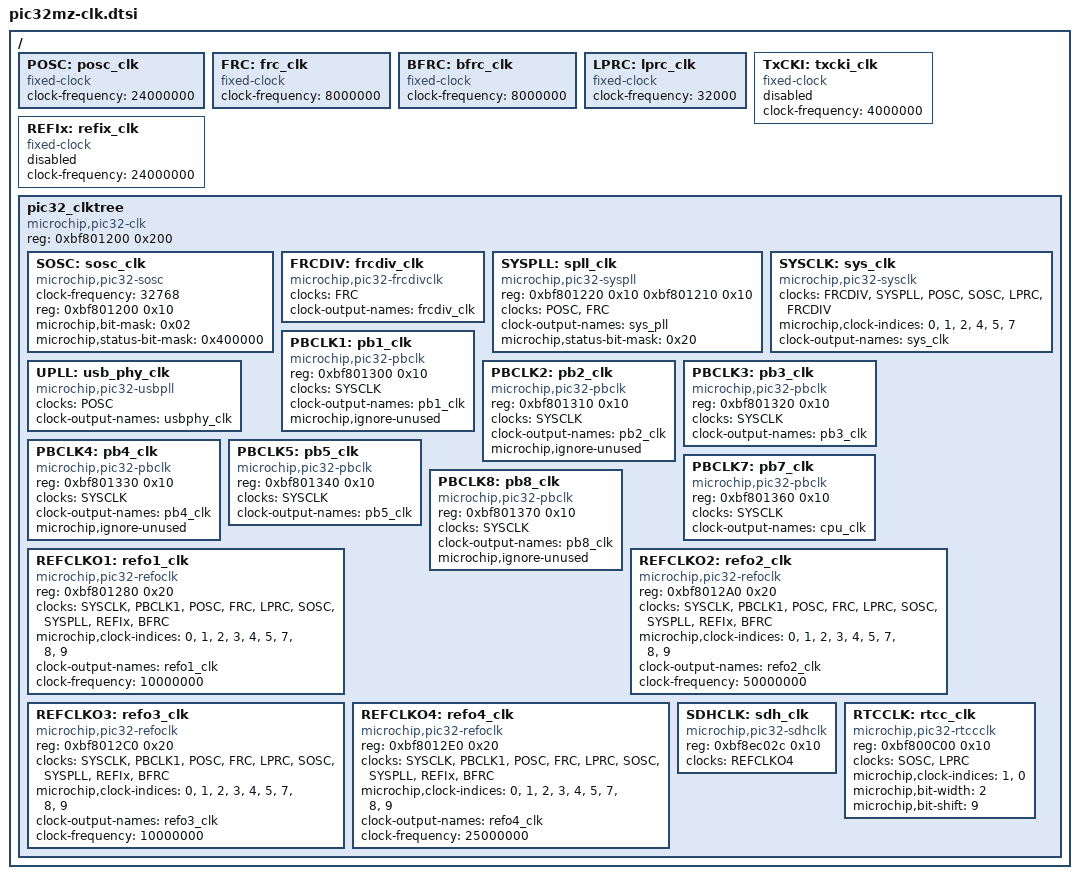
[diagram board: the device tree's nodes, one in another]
/*
 * Device Tree Source for PIC32MZ clock data
 *
 * Copyright (C) 2014 Microchip Technology, Inc.
 *               2014 Purna Chandra Mandal <purna.mandal@microchip.com>
 *
 * Licensed under GPLv2 or later.
 */

/* all fixed rate clocks */

/ {
	POSC:posc_clk { /* On-chip primary oscillator */
		#clock-cells = <0>;
		compatible = "fixed-clock";
		clock-frequency = <24000000>;
	};

	FRC:frc_clk { /* internal FRC oscillator */
		#clock-cells = <0>;
		compatible = "fixed-clock";
		clock-frequency = <8000000>;
	};

	BFRC:bfrc_clk { /* internal backup FRC oscillator */
		#clock-cells = <0>;
		compatible = "fixed-clock";
		clock-frequency = <8000000>;
	};

	LPRC:lprc_clk { /* internal low-power FRC oscillator */
		#clock-cells = <0>;
		compatible = "fixed-clock";
		clock-frequency = <32000>;
	};

	TxCKI:txcki_clk { /* external clock input on TxCLKI pin */
		#clock-cells = <0>;
		compatible = "fixed-clock";
		clock-frequency = <4000000>;
		status = "disabled";
	};

	/* external clock input on REFCLKIx pin */
	REFIx:refix_clk {
		#clock-cells = <0>;
		compatible = "fixed-clock";
		clock-frequency = <24000000>;
		status = "disabled";
	};

	/* PIC32 specifc clks */
	pic32_clktree {
		#address-cells = <1>;
		#size-cells = <1>;
		reg = <0xbf801200 0x200>;
		compatible = "microchip,pic32-clk";
		ranges;

		/* secondary oscillator; external input on SOSCI pin */
		SOSC:sosc_clk {
			#clock-cells = <0>;
			compatible = "microchip,pic32-sosc";
			clock-frequency = <32768>;
			reg = <0xbf801200 0x10>;
			microchip,bit-mask = <0x02>; /* enable mask */
			microchip,status-bit-mask = <0x400000>; /* status-mask*/
		};

		FRCDIV:frcdiv_clk {
			#clock-cells = <0>;
			compatible = "microchip,pic32-frcdivclk";
			clocks = <&FRC>;
			clock-output-names = "frcdiv_clk";
		};

		/* System PLL clock */
		SYSPLL:spll_clk {
			#clock-cells = <0>;
			compatible = "microchip,pic32-syspll";
			reg = <0xbf801220 0x10 /* SPLLCON */
			       0xbf801210 0x10 /* OSCCON */>;
			clocks = <&POSC>, <&FRC>;
			clock-output-names = "sys_pll";
			microchip,status-bit-mask = <0x20>; /* OSCCON.SLOCK */
		};

		/* system clock; mux */
		SYSCLK:sys_clk {
			#clock-cells = <0>;
			compatible = "microchip,pic32-sysclk";
			clocks = <&FRCDIV>,<&SYSPLL>,<&POSC>,<&SOSC>,<&LPRC>,<&FRCDIV>;
			microchip,clock-indices = <0>, <1>, <2>, <4>,    <5>,   <7>;
			clock-output-names = "sys_clk";
		};

		/* UPLL is integral part of USB PHY; generates UTMI clk for USBCORE */
		UPLL:usb_phy_clk {
			#clock-cells = <0>;
			compatible = "microchip,pic32-usbpll";
			clocks = <&POSC>;
			clock-output-names = "usbphy_clk";
		};

		/* Peripheral bus1 clock */
		PBCLK1:pb1_clk {
			reg = <0xbf801300 0x10>;
			#clock-cells = <0>;
			compatible = "microchip,pic32-pbclk";
			clocks = <&SYSCLK>;
			clock-output-names = "pb1_clk";
			microchip,ignore-unused; /* always ON, can't be gated even if unused */
		};

		/* Peripheral bus2(APB) clock */
		PBCLK2:pb2_clk {
			reg = <0xbf801310 0x10>;
			#clock-cells = <0>;
			compatible = "microchip,pic32-pbclk";
			clocks = <&SYSCLK>;
			clock-output-names = "pb2_clk";
			microchip,ignore-unused; /* avoid gating even if unused */
		};

		/* Peripheral bus3 clock */
		PBCLK3:pb3_clk {
			reg = <0xbf801320 0x10>;
			#clock-cells = <0>;
			compatible = "microchip,pic32-pbclk";
			clocks = <&SYSCLK>;
			clock-output-names = "pb3_clk";
		};

		/* Peripheral bus4 clock(I/O ports, GPIO) */
		PBCLK4:pb4_clk {
			reg = <0xbf801330 0x10>;
			#clock-cells = <0>;
			compatible = "microchip,pic32-pbclk";
			clocks = <&SYSCLK>;
			clock-output-names = "pb4_clk";
			/* I/O ports & GPIO controller uses this clock, so keep it enabled */
			microchip,ignore-unused;
		};

		/* Peripheral AHB bus clock */
		PBCLK5:pb5_clk {
			reg = <0xbf801340 0x10>;
			#clock-cells = <0>;
			compatible = "microchip,pic32-pbclk";
			clocks = <&SYSCLK>;
			clock-output-names = "pb5_clk";
		};

		/* Peripheral Bus7 clock; */
		PBCLK7:pb7_clk {
			reg = <0xbf801360 0x10>;
			compatible = "microchip,pic32-pbclk";
			clocks = <&SYSCLK>;
			#clock-cells = <0>;
			clock-output-names = "cpu_clk"; /* CPU is driven by this clock; so named */
		};

		/* Peripheral bus-8(EBI) clock */
		PBCLK8:pb8_clk {
			reg = <0xbf801370 0x10>;
			#clock-cells = <0>;
			compatible = "microchip,pic32-pbclk";
			clocks = <&SYSCLK>;
			clock-output-names = "pb8_clk";
			/* EBI drives SRAM in SK+MEB setup, so avoid gating even if unused */
			microchip,ignore-unused;
		};

		/* Reference Oscillator clock for SPI/I2S */
		REFCLKO1:refo1_clk {
			reg = <0xbf801280 0x20>;
			#clock-cells = <0>;
			compatible = "microchip,pic32-refoclk";
			clocks = <&SYSCLK>,<&PBCLK1>,<&POSC>,<&FRC>,<&LPRC>,<&SOSC>,<&SYSPLL>,<&REFIx>,<&BFRC>;
			microchip,clock-indices=<0>,<1>, <2>, <3>  , <4>   , <5>   ,  <7>    ,     <8>, <9>;
			clock-output-names = "refo1_clk";
			clock-frequency = <10000000>;  /* 10Mhz for I2S MCLK */
		};

		/* Reference Oscillator clock for SQI */
		REFCLKO2:refo2_clk {
			reg = <0xbf8012A0 0x20>;
			#clock-cells = <0>;
			compatible = "microchip,pic32-refoclk";
			clocks = <&SYSCLK>,<&PBCLK1>,<&POSC>,<&FRC>,<&LPRC>,<&SOSC>,<&SYSPLL>,<&REFIx>,<&BFRC>;
			microchip,clock-indices=<0>,<1>, <2>, <3>  , <4>   , <5>   ,  <7>    ,     <8>, <9>;
			clock-output-names = "refo2_clk";
			clock-frequency = <50000000>; /* 50MHz for SQI */
		};

		/* Reference Oscillator clock, ADC */
		REFCLKO3:refo3_clk {
			reg = <0xbf8012C0 0x20>;
			compatible = "microchip,pic32-refoclk";
			clocks = <&SYSCLK>,<&PBCLK1>,<&POSC>,<&FRC>,<&LPRC>,<&SOSC>,<&SYSPLL>,<&REFIx>,<&BFRC>;
			microchip,clock-indices=<0>,<1>, <2>, <3>  , <4>   , <5>   ,  <7>    ,     <8>, <9>;
			#clock-cells = <0>;
			clock-output-names = "refo3_clk";
			clock-frequency = <10000000>;  /* 1Mhz */
		};

		/* Reference Oscillator clock */
		REFCLKO4:refo4_clk {
			reg = <0xbf8012E0 0x20>;
			compatible = "microchip,pic32-refoclk";
			clocks = <&SYSCLK>,<&PBCLK1>,<&POSC>,<&FRC>,<&LPRC>,<&SOSC>,<&SYSPLL>,<&REFIx>,<&BFRC>;
			microchip,clock-indices=<0>,<1>, <2>, <3>  , <4>   , <5>   ,  <7>    ,     <8>, <9>;
			#clock-cells = <0>;
			clock-output-names = "refo4_clk";
			clock-frequency = <25000000>;  /* 25Mhz */
		};

		/* microchip,pic32-sdhc clock (stub - not used) */
		SDHCLK: sdh_clk {
			reg = <0xbf8ec02c 0x10>;
			#clock-cells = <0>;
			compatible = "microchip,pic32-sdhclk";
			clocks = <&REFCLKO4>;
		};

		/* Realtime Clock & Calender clock */
		RTCCLK: rtcc_clk {
			reg = <0xbf800C00 0x10>;
			#clock-cells = <0>;
			compatible = "microchip,pic32-rtccclk";
			clocks = <&SOSC>, <&LPRC>;
			microchip,clock-indices=<1>,<0>;
			microchip,bit-width = <2>;
			microchip,bit-shift = <9>;
		};
	};
};
